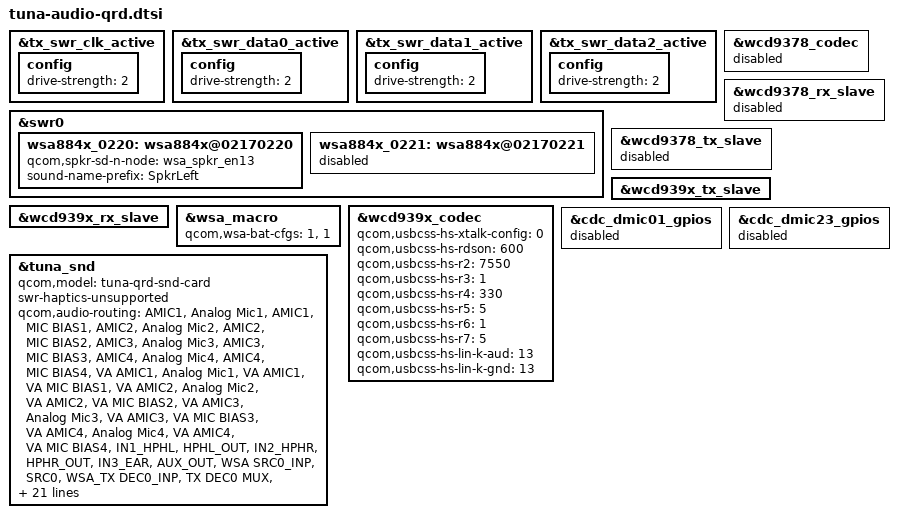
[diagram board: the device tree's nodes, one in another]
// SPDX-License-Identifier: BSD-3-Clause
/*
 * Copyright (c) 2023-2024 Qualcomm Innovation Center, Inc. All rights reserved.
 */
#include "tuna-audio-overlay.dtsi"
&tx_swr_clk_active {
	config {
		drive-strength = <2>;
	};
};

&tx_swr_data0_active {
	config {
		drive-strength = <2>;
	};
};

&tx_swr_data1_active {
	config {
		drive-strength = <2>;
	};
};

&tx_swr_data2_active {
	config {
		drive-strength = <2>;
	};
};

&swr0 {
	wsa884x_0220: wsa884x@02170220 {
		qcom,spkr-sd-n-node = <&wsa_spkr_en13>;
		sound-name-prefix = "SpkrLeft";
		status = "okay";
	};

	wsa884x_0221: wsa884x@02170221 {
		status = "disabled";
	};
};

&wcd9378_codec {
	status = "disabled";
};

&wcd9378_rx_slave {
	status = "disabled";
};

&wcd9378_tx_slave {
	status = "disabled";
};

&wcd939x_tx_slave {
	status = "okay";
};

&wcd939x_rx_slave {
	status = "okay";
};

&wsa_macro {
	qcom,wsa-bat-cfgs = <1>, <1>;
};

&wcd939x_codec {
	status = "okay";
	/* 0 for digital crosstalk disabled,
	 * 1 for digital crosstalk with local sensed a-xtalk enabled, and
	 * 2 for digital crosstalk with remote sensed a-xtalk enabled.
	 */
	qcom,usbcss-hs-xtalk-config = <0>;
	qcom,usbcss-hs-rdson = <600>;
	qcom,usbcss-hs-r2 = <7550>;
	qcom,usbcss-hs-r3 = <1>;
	qcom,usbcss-hs-r4 = <330>;
	qcom,usbcss-hs-r5 = <5>;
	qcom,usbcss-hs-r6 = <1>;
	qcom,usbcss-hs-r7 = <5>;
	qcom,usbcss-hs-lin-k-aud = <13>;
	qcom,usbcss-hs-lin-k-gnd = <13>;
};

&cdc_dmic01_gpios {
	status = "disabled";
};

&cdc_dmic23_gpios {
	status = "disabled";
};

&tuna_snd {
	qcom,model = "tuna-qrd-snd-card";
	swr-haptics-unsupported;
	qcom,audio-routing =
		"AMIC1", "Analog Mic1",
		"AMIC1", "MIC BIAS1",
		"AMIC2", "Analog Mic2",
		"AMIC2", "MIC BIAS2",
		"AMIC3", "Analog Mic3",
		"AMIC3", "MIC BIAS3",
		"AMIC4", "Analog Mic4",
		"AMIC4", "MIC BIAS4",
		"VA AMIC1", "Analog Mic1",
		"VA AMIC1", "VA MIC BIAS1",
		"VA AMIC2", "Analog Mic2",
		"VA AMIC2", "VA MIC BIAS2",
		"VA AMIC3", "Analog Mic3",
		"VA AMIC3", "VA MIC BIAS3",
		"VA AMIC4", "Analog Mic4",
		"VA AMIC4", "VA MIC BIAS4",
		"IN1_HPHL", "HPHL_OUT",
		"IN2_HPHR", "HPHR_OUT",
		"IN3_EAR", "AUX_OUT",
		"WSA SRC0_INP", "SRC0",
		"WSA_TX DEC0_INP", "TX DEC0 MUX",
		"WSA_TX DEC1_INP", "TX DEC1 MUX",
		"RX_TX DEC0_INP", "TX DEC0 MUX",
		"RX_TX DEC1_INP", "TX DEC1 MUX",
		"RX_TX DEC2_INP", "TX DEC2 MUX",
		"RX_TX DEC3_INP", "TX DEC3 MUX",
		"SpkrLeft IN", "WSA_SPK1 OUT",
		"TX SWR_INPUT", "WCD_TX_OUTPUT",
		"VA SWR_INPUT", "VA_SWR_CLK",
		"VA SWR_INPUT", "WCD_TX_OUTPUT",
		"VA_AIF1 CAP", "VA_SWR_CLK",
		"VA_AIF2 CAP", "VA_SWR_CLK",
		"VA_AIF3 CAP", "VA_SWR_CLK";
	asoc-codec  = <&stub_codec>, <&lpass_cdc>,
			<&wcd939x_codec>, <&wsa884x_0220>;
	asoc-codec-names = "msm-stub-codec.1", "lpass-cdc",
			"wcd939x_codec", "wsa-codec1";
	qcom,ext-disp-audio-rx = <1>;
	qcom,wsa-max-devs = <1>;
	qcom,wcd-disable-legacy-surge;
	wcd939x-i2c-handle = <&wcd_usbss>;
	qcom,msm-mbhc-usbc-audio-supported = <1>;
	qcom,msm-mbhc-hphl-swh = <0>;
	qcom,msm-mbhc-gnd-swh = <0>;
	qcom,msm-mbhc-hs-mic-max-threshold-mv = <1670>;
};


